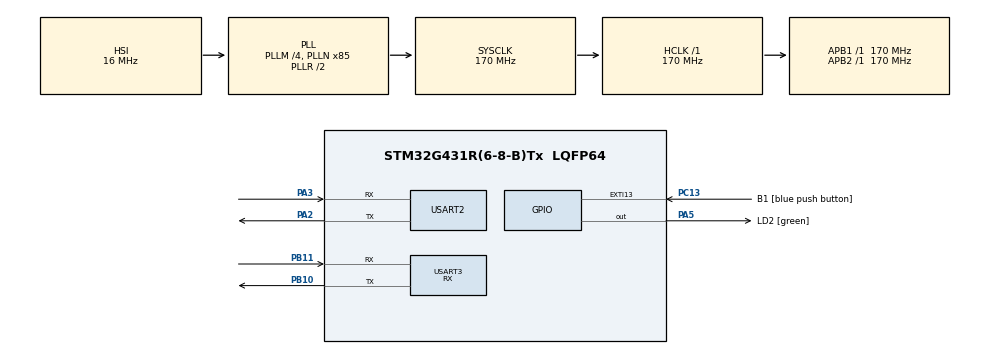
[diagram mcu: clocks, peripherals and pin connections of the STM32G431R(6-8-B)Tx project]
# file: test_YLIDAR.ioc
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Dma.Request0=USART3_RX
Dma.USART3_RX.0.Direction=DMA_PERIPH_TO_MEMORY
Dma.USART3_RX.0.EventEnable=DISABLE
Dma.USART3_RX.0.Instance=DMA1_Channel1
Dma.USART3_RX.0.MemDataAlignment=DMA_MDATAALIGN_BYTE
Dma.USART3_RX.0.MemInc=DMA_MINC_ENABLE
Dma.USART3_RX.0.Mode=DMA_CIRCULAR
Dma.USART3_RX.0.PeriphDataAlignment=DMA_PDATAALIGN_BYTE
Dma.USART3_RX.0.PeriphInc=DMA_PINC_DISABLE
Dma.USART3_RX.0.Polarity=HAL_DMAMUX_REQ_GEN_RISING
Dma.USART3_RX.0.Priority=DMA_PRIORITY_LOW
Dma.USART3_RX.0.RequestNumber=1
Dma.USART3_RX.0.SignalID=NONE
Dma.USART3_RX.0.SyncEnable=DISABLE
Dma.USART3_RX.0.SyncPolarity=HAL_DMAMUX_SYNC_NO_EVENT
Dma.USART3_RX.0.SyncRequestNumber=1
Dma.USART3_RX.0.SyncSignalID=NONE
Mcu.Family=STM32G4
Mcu.Name=STM32G431R(6-8-B)Tx
Mcu.Package=LQFP64
NVIC.DMA1_Channel1_IRQn=true\:0\:0\:false\:false\:true\:false\:true\:true
NVIC.PriorityGroup=NVIC_PRIORITYGROUP_4
NVIC.USART3_IRQn=true\:0\:0\:false\:false\:true\:true\:true\:true
PA10.Signal=USART1_RX
PA13.GPIO_Label=T_SWDIO
PA13.Signal=SYS_JTMS-SWDIO
PA14.GPIO_Label=T_SWCLK
PA14.Signal=SYS_JTCK-SWCLK
PA2.Mode=Asynchronous
PA2.Signal=USART2_TX
PA3.Mode=Asynchronous
PA3.Signal=USART2_RX
PA5.GPIO_Label=LD2 [green]
PA5.Signal=GPIO_Output
PA9.Signal=USART1_TX
PB10.Mode=Asynchronous
PB10.Signal=USART3_TX
PB11.Mode=Asynchronous
PB11.Signal=USART3_RX
PB3.GPIO_Label=T_SWO
PB3.Signal=SYS_JTDO-SWO
PC13.GPIO_Label=B1 [blue push button]
PC13.Signal=GPXTI13
PC14-OSC32_IN.GPIO_Label=RCC_OSC32_OUT
PC14-OSC32_IN.Signal=RCC_OSC32_IN
PC15-OSC32_OUT.GPIO_Label=RCC_OSC32_OUT
PC15-OSC32_OUT.Signal=RCC_OSC32_OUT
PF0-OSC_IN.GPIO_Label=RCC_OSC_IN
PF0-OSC_IN.Signal=RCC_OSC_IN
PF1-OSC_OUT.GPIO_Label=RCC_OSC_OUT
PF1-OSC_OUT.Signal=RCC_OSC_OUT
ProjectManager.HeapSize=0x200
ProjectManager.StackSize=0x400
ProjectManager.TargetToolchain=STM32CubeIDE
RCC.ADC12Freq_Value=170000000
RCC.AHBFreq_Value=170000000
RCC.APB1Freq_Value=170000000
RCC.APB1TimFreq_Value=170000000
RCC.APB2Freq_Value=170000000
RCC.APB2TimFreq_Value=170000000
RCC.CortexFreq_Value=170000000
RCC.EXTERNAL_CLOCK_VALUE=12288000
RCC.HCLKFreq_Value=170000000
RCC.HSE_VALUE=24000000
RCC.HSI48_VALUE=48000000
RCC.HSI_VALUE=16000000
RCC.LSE_VALUE=32768
RCC.PLLM=RCC_PLLM_DIV4
RCC.PLLN=85
RCC.RTCClockSelection=RCC_RTCCLKSOURCE_LSE
RCC.SYSCLKFreq_VALUE=170000000
RCC.SYSCLKSource=RCC_SYSCLKSOURCE_PLLCLK
RCC.USBFreq_Value=170000000
RCC.VCOOutputFreq_Value=340000000
USART2.VirtualMode-Asynchronous=VM_ASYNC
USART3.Mode=MODE_RX
USART3.VirtualMode-Asynchronous=VM_ASYNC
VP_SYS_VS_DBSignals.Mode=DisableDeadBatterySignals
board=NUCLEO-G431RB

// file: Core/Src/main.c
/* USER CODE BEGIN Header */
/**
 ******************************************************************************
 * @file           : main.c
 * @brief          : Main program body
 ******************************************************************************
 * @attention
 *
 * Copyright (c) 2024 STMicroelectronics.
 * All rights reserved.
 *
 * This software is licensed under terms that can be found in the LICENSE file
 * in the root directory of this software component.
 * If no LICENSE file comes with this software, it is provided AS-IS.
 *
 ******************************************************************************
 * @note
 * Details on the YLIDAR used for this project can be found at:
 * https://www.ydlidar.com/products/view/6.html
 *
 ******************************************************************************
 */
/* USER CODE END Header */
#include "main.h"
#include "dma.h"
#include "usart.h"
#include "gpio.h"

/* USER CODE BEGIN Includes */
#include <stdio.h>
#include <stdlib.h>
#include "ylidarx2.h"

/* USER CODE END Includes */

/* USER CODE BEGIN PD */
#define DEBUG 1 // Enable debug logs

#if DEBUG
#include <stdio.h>
#define DEBUG_PRINT(...) printf(__VA_ARGS__)
#else
#define DEBUG_PRINT(...)
#endif

/* USER CODE END PD */

void SystemClock_Config(void);

/* USER CODE BEGIN 0 */
/**
 * @brief Transmit a character over UART.
 * @param ch: Character to transmit.
 * @retval int: The transmitted character.
 */
int __io_putchar(int ch)
{
	HAL_UART_Transmit(&huart2, (uint8_t *)&ch, 1, HAL_MAX_DELAY);

	return ch;
}

// Global LIDAR object
YLIDARX2_t lidar;

/**
 * @brief UART receive half complete callback.
 * @param huart: Pointer to the UART handle
 * @retval None
 */
void HAL_UART_RxHalfCpltCallback(UART_HandleTypeDef *huart) {
	if (huart->Instance == USART3) {
		YLIDARX2_ProcessDMAHalfComplete(&lidar);
	}
}

/**
 * @brief UART receive complete callback.
 * @param huart: Pointer to the UART handle
 * @retval None
 */
void HAL_UART_RxCpltCallback(UART_HandleTypeDef *huart) {
	if (huart->Instance == USART3) {
		YLIDARX2_ProcessDMAComplete(&lidar);
	}
}

/**
 * @brief UART error callback.
 * @param huart: Pointer to the UART handle
 * @retval None
 */
void HAL_UART_ErrorCallback(UART_HandleTypeDef *huart)
{
	if (huart->Instance == USART3)
	{
		if (HAL_UART_GetError(huart) & HAL_UART_ERROR_PE)
			DEBUG_PRINT("Parity Error!\r\n");
		if (HAL_UART_GetError(huart) & HAL_UART_ERROR_NE)
			DEBUG_PRINT("Noise Error!\r\n");
		if (HAL_UART_GetError(huart) & HAL_UART_ERROR_FE)
			DEBUG_PRINT("Framing Error!\r\n");
		if (HAL_UART_GetError(huart) & HAL_UART_ERROR_ORE)
			DEBUG_PRINT("Overrun Error!\r\n");
	}
}

/* USER CODE END 0 */

int main(void)
{

	/* MCU Configuration--------------------------------------------------------*/

	/* Reset of all peripherals, Initializes the Flash interface and the Systick. */
	HAL_Init();

	/* Configure the system clock */
	SystemClock_Config();

	/* Initialize all configured peripherals */
	MX_GPIO_Init();
	MX_DMA_Init();
	MX_USART2_UART_Init();
	MX_USART3_UART_Init();
	/* USER CODE BEGIN 2 */
	printf("\r\n***** TEST YLIDAR X2 *****\r\n");

	// Initialize LIDAR with DMA
	YLIDARX2_InitDMA(&lidar, &huart3);

	/* USER CODE END 2 */

	/* Infinite loop */
	while (1)
	{

	}
}

void SystemClock_Config(void)
{
	RCC_OscInitTypeDef RCC_OscInitStruct = {0};
	RCC_ClkInitTypeDef RCC_ClkInitStruct = {0};

	/** Configure the main internal regulator output voltage
	 */
	HAL_PWREx_ControlVoltageScaling(PWR_REGULATOR_VOLTAGE_SCALE1_BOOST);

	/** Initializes the RCC Oscillators according to the specified parameters
	 * in the RCC_OscInitTypeDef structure.
	 */
	RCC_OscInitStruct.OscillatorType = RCC_OSCILLATORTYPE_HSI;
	RCC_OscInitStruct.HSIState = RCC_HSI_ON;
	RCC_OscInitStruct.HSICalibrationValue = RCC_HSICALIBRATION_DEFAULT;
	RCC_OscInitStruct.PLL.PLLState = RCC_PLL_ON;
	RCC_OscInitStruct.PLL.PLLSource = RCC_PLLSOURCE_HSI;
	RCC_OscInitStruct.PLL.PLLM = RCC_PLLM_DIV4;
	RCC_OscInitStruct.PLL.PLLN = 85;
	RCC_OscInitStruct.PLL.PLLP = RCC_PLLP_DIV2;
	RCC_OscInitStruct.PLL.PLLQ = RCC_PLLQ_DIV2;
	RCC_OscInitStruct.PLL.PLLR = RCC_PLLR_DIV2;
	if (HAL_RCC_OscConfig(&RCC_OscInitStruct) != HAL_OK)
	{
		Error_Handler();
	}

	/** Initializes the CPU, AHB and APB buses clocks
	 */
	RCC_ClkInitStruct.ClockType = RCC_CLOCKTYPE_HCLK|RCC_CLOCKTYPE_SYSCLK
			|RCC_CLOCKTYPE_PCLK1|RCC_CLOCKTYPE_PCLK2;
	RCC_ClkInitStruct.SYSCLKSource = RCC_SYSCLKSOURCE_PLLCLK;
	RCC_ClkInitStruct.AHBCLKDivider = RCC_SYSCLK_DIV1;
	RCC_ClkInitStruct.APB1CLKDivider = RCC_HCLK_DIV1;
	RCC_ClkInitStruct.APB2CLKDivider = RCC_HCLK_DIV1;

	if (HAL_RCC_ClockConfig(&RCC_ClkInitStruct, FLASH_LATENCY_4) != HAL_OK)
	{
		Error_Handler();
	}
}

void Error_Handler(void)
{
	__disable_irq();
	while (1)
	{
	}
}
